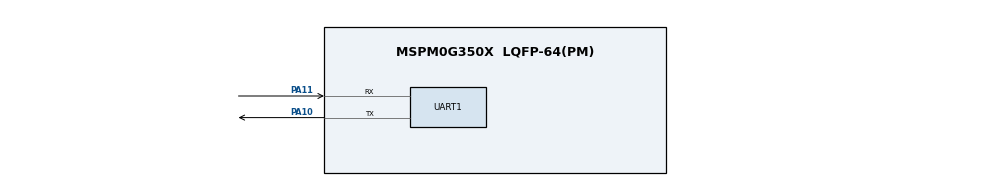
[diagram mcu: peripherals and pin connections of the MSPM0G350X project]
/**
 * @cliArgs --device "MSPM0G350X" --part "Default" --package "LQFP-64(PM)" --product "mspm0_sdk@2.04.00.06"
 * @versions {"tool":"1.22.0+3893"}
 */

/**
 * Import the modules used in this configuration.
 */
const ADC12         = scripting.addModule("/ti/driverlib/ADC12", {}, false);
const ADC121        = ADC12.addInstance();
const Board         = scripting.addModule("/ti/driverlib/Board");
const MATHACL       = scripting.addModule("/ti/driverlib/MATHACL");
const SYSCTL        = scripting.addModule("/ti/driverlib/SYSCTL");
const SYSTICK       = scripting.addModule("/ti/driverlib/SYSTICK");
const UART          = scripting.addModule("/ti/driverlib/UART", {}, false);
const UART1         = UART.addInstance();
const ProjectConfig = scripting.addModule("/ti/project_config/ProjectConfig");

/**
 * Write custom configuration values to the imported modules.
 */
ADC121.$name                          = "ADC12_0";
ADC121.repeatMode                     = true;
ADC121.sampleTime0                    = "62.5 ns";
ADC121.powerDownMode                  = "DL_ADC12_POWER_DOWN_MODE_MANUAL";
ADC121.enableFIFO                     = true;
ADC121.configureDMA                   = true;
ADC121.sampCnt                        = 6;
ADC121.enabledDMATriggers             = ["DL_ADC12_DMA_MEM10_RESULT_LOADED"];
ADC121.enabledInterrupts              = ["DL_ADC12_INTERRUPT_DMA_DONE"];
ADC121.adcMem0chansel                 = "DL_ADC12_INPUT_CHAN_4";
ADC121.peripheral.$assign             = "ADC0";
ADC121.DMA_CHANNEL.$name              = "DMA_CH0";
ADC121.DMA_CHANNEL.addressMode        = "f2b";
ADC121.DMA_CHANNEL.transferMode       = "FULL_CH_REPEAT_SINGLE";
ADC121.DMA_CHANNEL.peripheral.$assign = "DMA_CH0";
ADC121.adcPin4Config.$name            = "ti_driverlib_gpio_GPIOPinGeneric0";


SYSCTL.forceDefaultClkConfig = true;
SYSCTL.clockTreeEn           = true;

SYSTICK.periodEnable      = true;
SYSTICK.period            = 32000;
SYSTICK.interruptEnable   = true;
SYSTICK.systickEnable     = true;
SYSTICK.interruptPriority = "0";

UART1.$name                       = "UART_0";
UART1.enableDMATX                 = false;
UART1.enableFIFO                  = true;
UART1.rxFifoThreshold             = "DL_UART_RX_FIFO_LEVEL_ONE_ENTRY";
UART1.enabledInterrupts           = ["DMA_DONE_RX"];
UART1.enabledDMARXTriggers        = "DL_UART_DMA_INTERRUPT_RX";
UART1.targetBaudRate              = 921600;
UART1.peripheral.$assign          = "UART0";
UART1.peripheral.rxPin.$assign    = "PA11";
UART1.peripheral.txPin.$assign    = "PA10";
UART1.txPinConfig.$name           = "ti_driverlib_gpio_GPIOPinGeneric1";
UART1.rxPinConfig.$name           = "ti_driverlib_gpio_GPIOPinGeneric2";
UART1.DMA_CHANNEL_RX.$name        = "DMA_CH1";
UART1.DMA_CHANNEL_RX.srcLength    = "BYTE";
UART1.DMA_CHANNEL_RX.dstLength    = "BYTE";
UART1.DMA_CHANNEL_RX.transferMode = "FULL_CH_REPEAT_SINGLE";
UART1.DMA_CHANNEL_RX.addressMode  = "f2b";

ProjectConfig.genLibIQ        = true;
ProjectConfig.genLibIQVersion = "MATHACL";
ProjectConfig.genLibCMSIS     = true;

/**
 * Pinmux solution for unlocked pins/peripherals. This ensures that minor changes to the automatic solver in a future
 * version of the tool will not impact the pinmux you originally saw.  These lines can be completely deleted in order to
 * re-solve from scratch.
 */
ADC121.peripheral.adcPin4.$suggestSolution       = "PB25";
Board.peripheral.$suggestSolution                = "DEBUGSS";
Board.peripheral.swclkPin.$suggestSolution       = "PA20";
Board.peripheral.swdioPin.$suggestSolution       = "PA19";
UART1.DMA_CHANNEL_RX.peripheral.$suggestSolution = "DMA_CH1";
